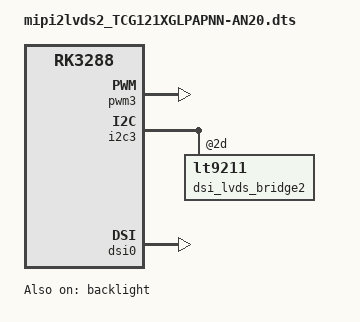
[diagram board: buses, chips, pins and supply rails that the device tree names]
/dts-v1/;
/plugin/;
/ {
	compatible = "rockchip,rk3288-evb-android-rk808-edp", "rockchip,rk3288";

	fragment@0 {
		target = <&pwm3>;
		__overlay__ {
			status = "okay";
		};
	};
	fragment@1 {
		target = <&backlight>;
		__overlay__ {
			status = "okay";
			pwms = <&pwm3 0 500000 0>;
            minimal-brightness-level = <30>;
		};
	};
	fragment@2 {
		target = <&i2c3>;
		__overlay__ {
			status = "okay";
			dsi_lvds_bridge2: lt9211@2d {
				status = "okay";
				dsi-lanes = <2>;
				lvds-format = <2>;//VESA
				lvds-bpp = <24>;
                de-mode;
				reg33 = /bits/ 8 <0x02>;
				reg35 = /bits/ 8 <0x04>;
				//test-pattern;
			};
		};
	};
	fragment@3 {
		target = <&dsi0>;
		__overlay__ {
			status = "okay";
			panel@0 {
				backlight = <&backlight>;

				width-mm = <245>;
				height-mm = <184>;
				bpc=<8>;
				bus-format = <0x100a>;//<MEDIA_BUS_FMT_RGB888_1X24>;
				dsi,flags = <0x3>;
				dsi,format = <0>;
				dsi,lanes = <2>;

				t1=<15>;//VCC on to start lvds signal
				t2=<200>;//LVDS signal(start) to turn Backlihgt on
				t3=<200>;//Backlihgt(off) to stop lvds signal
				t4=<0>;//LVDS signal to turn VCC off
				t5=<2000>;//VCC off to turn VCC on

				display-timings {
					native-mode = <&timing84>;

					timing84: timing84  {
						clock-frequency = <65000000>;
						hactive = <1024>;
						vactive = <768>;
						hfront-porch = <128>;
						hback-porch = <64>;
						hsync-len = <128>;
						vfront-porch = <14>;
						vsync-len = <10>;
						vback-porch = <14>;
						hsync-active = <0>;
						vsync-active = <0>;
						de-active = <1>;
						pixelclk-active = <0>;
					};
				};
			};
		};
	};
};
